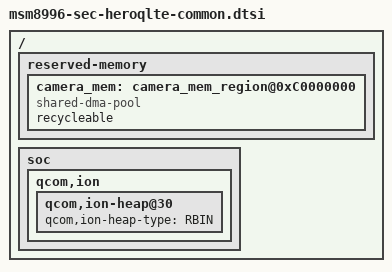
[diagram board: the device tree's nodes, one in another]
/* Copyright (c) 2015, The Linux Foundation. All rights reserved.
 *
 * This program is free software; you can redistribute it and/or modify
 * it under the terms of the GNU General Public License version 2 and
 * only version 2 as published by the Free Software Foundation.
 *
 * This program is distributed in the hope that it will be useful,
 * but WITHOUT ANY WARRANTY; without even the implied warranty of
 * MERCHANTABILITY or FITNESS FOR A PARTICULAR PURPOSE.  See the
 * GNU General Public License for more details.
 */

/ {
	reserved-memory {
		/* Reserved Mem for Camera */
		camera_mem: camera_mem_region@0xC0000000 {
			compatible = "shared-dma-pool";
			recycleable;
		};
	};

	soc {
		qcom,ion {
			qcom,ion-heap@30 { /* Reserved Mem for Camera */
				qcom,ion-heap-type = "RBIN";
			};
		};
	};
};
